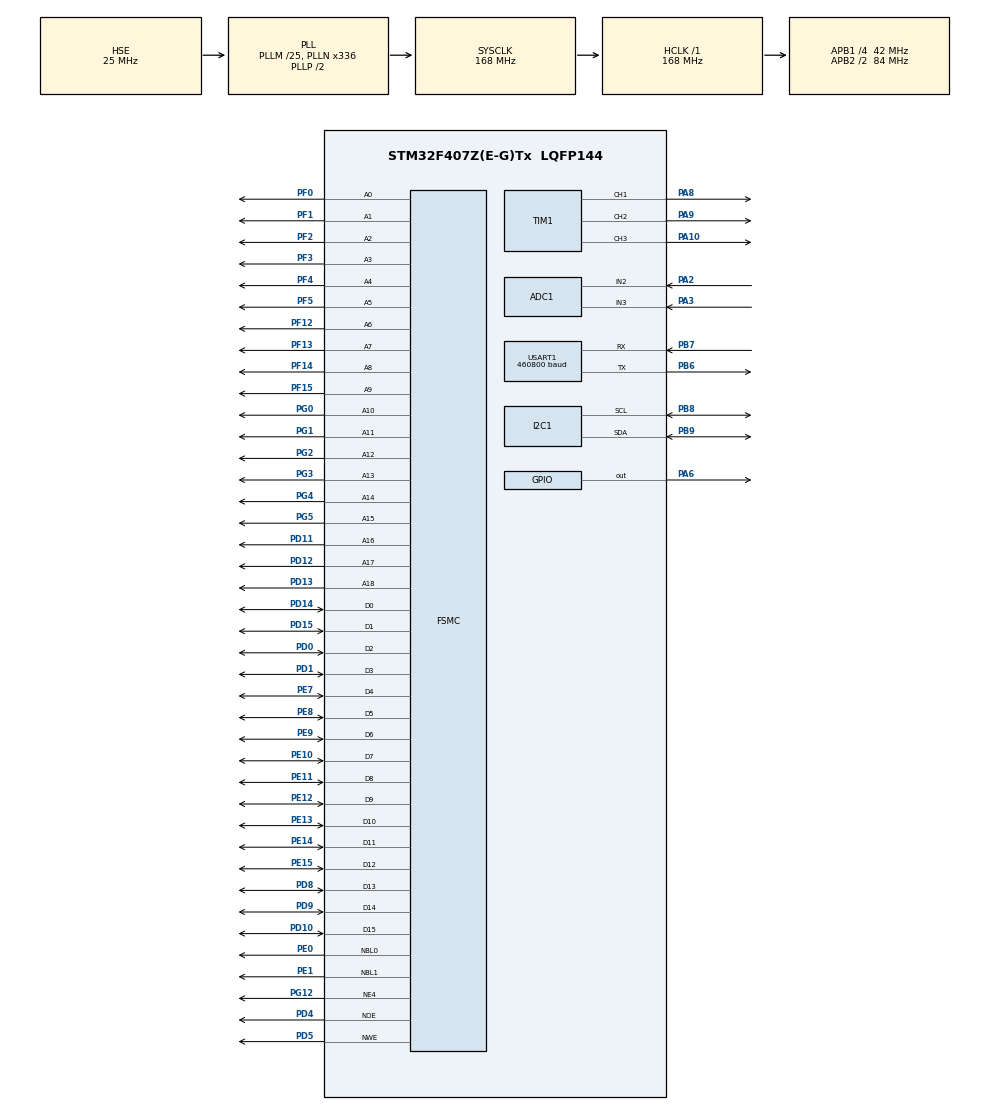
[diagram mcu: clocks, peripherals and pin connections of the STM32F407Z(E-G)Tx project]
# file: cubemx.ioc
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ADC1.Channel-6\#ChannelRegularConversion=ADC_CHANNEL_3
ADC1.Channel-7\#ChannelInjectedConversion=ADC_CHANNEL_2
ADC1.Channel-9\#ChannelInjectedConversion=ADC_CHANNEL_3
ADC1.ExternalTrigInjecConv=ADC_EXTERNALTRIGINJECCONV_T1_TRGO
ADC1.InjNumberOfConversion=2
ADC1.InjectedOffset-7\#ChannelInjectedConversion=0
ADC1.InjectedOffset-9\#ChannelInjectedConversion=0
ADC1.InjectedRank-7\#ChannelInjectedConversion=1
ADC1.InjectedRank-9\#ChannelInjectedConversion=2
ADC1.NbrOfConversion=1
ADC1.NbrOfConversionFlag=1
ADC1.Rank-6\#ChannelRegularConversion=1
ADC1.SamplingTime-6\#ChannelRegularConversion=ADC_SAMPLETIME_3CYCLES
ADC1.SamplingTime-7\#ChannelInjectedConversion=ADC_SAMPLETIME_15CYCLES
ADC1.SamplingTime-9\#ChannelInjectedConversion=ADC_SAMPLETIME_15CYCLES
ADC1.master=1
FSMC.WriteOperation1=FSMC_WRITE_OPERATION_ENABLE
I2C1.I2C_Mode=I2C_Fast
Mcu.Family=STM32F4
Mcu.Name=STM32F407Z(E-G)Tx
Mcu.Package=LQFP144
NVIC.ADC_IRQn=true\:0\:0\:false\:false\:true\:true\:true\:true
NVIC.PriorityGroup=NVIC_PRIORITYGROUP_4
NVIC.TIM1_UP_TIM10_IRQn=true\:0\:0\:false\:false\:true\:true\:true\:true
NVIC.TIM2_IRQn=true\:0\:0\:false\:false\:true\:true\:true\:true
PA10.Signal=S_TIM1_CH3
PA2.Signal=ADCx_IN2
PA3.Signal=ADCx_IN3
PA6.GPIO_Speed=GPIO_SPEED_FREQ_MEDIUM
PA6.Signal=GPIO_Output
PA8.Signal=S_TIM1_CH1
PA9.Signal=S_TIM1_CH2
PB6.Mode=Asynchronous
PB6.Signal=USART1_TX
PB7.Mode=Asynchronous
PB7.Signal=USART1_RX
PB8.Mode=I2C
PB8.Signal=I2C1_SCL
PB9.Mode=I2C
PB9.Signal=I2C1_SDA
PD0.Signal=FSMC_D2_DA2
PD1.Signal=FSMC_D3_DA3
PD10.Signal=FSMC_D15_DA15
PD11.Signal=FSMC_A16_CLE
PD12.Signal=FSMC_A17_ALE
PD13.Signal=FSMC_A18
PD14.Signal=FSMC_D0_DA0
PD15.Signal=FSMC_D1_DA1
PD4.Signal=FSMC_NOE
PD5.Signal=FSMC_NWE
PD8.Signal=FSMC_D13_DA13
PD9.Signal=FSMC_D14_DA14
PE0.Signal=FSMC_NBL0
PE1.Signal=FSMC_NBL1
PE10.Signal=FSMC_D7_DA7
PE11.Signal=FSMC_D8_DA8
PE12.Signal=FSMC_D9_DA9
PE13.Signal=FSMC_D10_DA10
PE14.Signal=FSMC_D11_DA11
PE15.Signal=FSMC_D12_DA12
PE7.Signal=FSMC_D4_DA4
PE8.Signal=FSMC_D5_DA5
PE9.Signal=FSMC_D6_DA6
PF0.Signal=FSMC_A0
PF1.Signal=FSMC_A1
PF12.Signal=FSMC_A6
PF13.Signal=FSMC_A7
PF14.Signal=FSMC_A8
PF15.Signal=FSMC_A9
PF2.Signal=FSMC_A2
PF3.Signal=FSMC_A3
PF4.Signal=FSMC_A4
PF5.Signal=FSMC_A5
PG0.Signal=FSMC_A10
PG1.Signal=FSMC_A11
PG12.Mode=NorPsramChipSelect4_1
PG12.Signal=FSMC_NE4
PG2.Signal=FSMC_A12
PG3.Signal=FSMC_A13
PG4.Signal=FSMC_A14
PG5.Signal=FSMC_A15
PH0-OSC_IN.Mode=HSE-External-Oscillator
PH0-OSC_IN.Signal=RCC_OSC_IN
PH1-OSC_OUT.Mode=HSE-External-Oscillator
PH1-OSC_OUT.Signal=RCC_OSC_OUT
ProjectManager.HeapSize=0x200
ProjectManager.StackSize=0x400
ProjectManager.TargetToolchain=EWARM V8.50
RCC.48MHZClocksFreq_Value=84000000
RCC.AHBFreq_Value=168000000
RCC.APB1CLKDivider=RCC_HCLK_DIV4
RCC.APB1Freq_Value=42000000
RCC.APB1TimFreq_Value=84000000
RCC.APB2CLKDivider=RCC_HCLK_DIV2
RCC.APB2Freq_Value=84000000
RCC.APB2TimFreq_Value=168000000
RCC.CortexFreq_Value=168000000
RCC.HCLKFreq_Value=168000000
RCC.HSE_VALUE=25000000
RCC.HSI_VALUE=16000000
RCC.LSE_VALUE=32768
RCC.PLLM=25
RCC.PLLN=336
RCC.PLLSourceVirtual=RCC_PLLSOURCE_HSE
RCC.SYSCLKFreq_VALUE=168000000
RCC.SYSCLKSource=RCC_SYSCLKSOURCE_PLLCLK
RCC.VCOOutputFreq_Value=336000000
SH.ADCx_IN2.0=ADC1_IN2,IN2
SH.ADCx_IN3.0=ADC1_IN3,IN3
SH.FSMC_A0.0=FSMC_A0,19b-a1
SH.FSMC_A1.0=FSMC_A1,19b-a1
SH.FSMC_A10.0=FSMC_A10,19b-a1
SH.FSMC_A11.0=FSMC_A11,19b-a1
SH.FSMC_A12.0=FSMC_A12,19b-a1
SH.FSMC_A13.0=FSMC_A13,19b-a1
SH.FSMC_A14.0=FSMC_A14,19b-a1
SH.FSMC_A15.0=FSMC_A15,19b-a1
SH.FSMC_A16_CLE.0=FSMC_A16,19b-a1
SH.FSMC_A17_ALE.0=FSMC_A17,19b-a1
SH.FSMC_A18.0=FSMC_A18,19b-a1
SH.FSMC_A2.0=FSMC_A2,19b-a1
SH.FSMC_A3.0=FSMC_A3,19b-a1
SH.FSMC_A4.0=FSMC_A4,19b-a1
SH.FSMC_A5.0=FSMC_A5,19b-a1
SH.FSMC_A6.0=FSMC_A6,19b-a1
SH.FSMC_A7.0=FSMC_A7,19b-a1
SH.FSMC_A8.0=FSMC_A8,19b-a1
SH.FSMC_A9.0=FSMC_A9,19b-a1
SH.FSMC_D0_DA0.0=FSMC_D0,16b-d1
SH.FSMC_D10_DA10.0=FSMC_D10,16b-d1
SH.FSMC_D11_DA11.0=FSMC_D11,16b-d1
SH.FSMC_D12_DA12.0=FSMC_D12,16b-d1
SH.FSMC_D13_DA13.0=FSMC_D13,16b-d1
SH.FSMC_D14_DA14.0=FSMC_D14,16b-d1
SH.FSMC_D15_DA15.0=FSMC_D15,16b-d1
SH.FSMC_D1_DA1.0=FSMC_D1,16b-d1
SH.FSMC_D2_DA2.0=FSMC_D2,16b-d1
SH.FSMC_D3_DA3.0=FSMC_D3,16b-d1
SH.FSMC_D4_DA4.0=FSMC_D4,16b-d1
SH.FSMC_D5_DA5.0=FSMC_D5,16b-d1
SH.FSMC_D6_DA6.0=FSMC_D6,16b-d1
SH.FSMC_D7_DA7.0=FSMC_D7,16b-d1
SH.FSMC_D8_DA8.0=FSMC_D8,16b-d1
SH.FSMC_D9_DA9.0=FSMC_D9,16b-d1
SH.FSMC_NBL0.0=FSMC_NBL0,2ByteEnable1
SH.FSMC_NBL1.0=FSMC_NBL1,2ByteEnable1
SH.FSMC_NOE.0=FSMC_NOE,Sram1
SH.FSMC_NWE.0=FSMC_NWE,Sram1
SH.S_TIM1_CH1.0=TIM1_CH1,PWM Generation1 CH1
SH.S_TIM1_CH2.0=TIM1_CH2,PWM Generation2 CH2
SH.S_TIM1_CH3.0=TIM1_CH3,PWM Generation3 CH3
TIM1.AutoReloadPreload=TIM_AUTORELOAD_PRELOAD_ENABLE
TIM1.Channel-PWM\ Generation1\ CH1=TIM_CHANNEL_1
TIM1.Channel-PWM\ Generation2\ CH2=TIM_CHANNEL_2
TIM1.Channel-PWM\ Generation3\ CH3=TIM_CHANNEL_3
TIM1.CounterMode=TIM_COUNTERMODE_CENTERALIGNED1
TIM1.Period=(168000/15/2)-1
TIM1.Pulse-PWM\ Generation1\ CH1=0
TIM1.Pulse-PWM\ Generation2\ CH2=0
TIM1.Pulse-PWM\ Generation3\ CH3=0
TIM1.RepetitionCounter=1
TIM1.TIM_MasterOutputTrigger=TIM_TRGO_UPDATE
TIM1.TIM_MasterSlaveMode=TIM_MASTERSLAVEMODE_ENABLE
TIM2.AutoReloadPreload=TIM_AUTORELOAD_PRELOAD_ENABLE
TIM2.Period=499
TIM2.Prescaler=168-1
USART1.BaudRate=460800
USART1.VirtualMode=VM_ASYNC
VP_TIM1_VS_ClockSourceINT.Mode=Internal
VP_TIM2_VS_ClockSourceINT.Mode=Internal
board=custom

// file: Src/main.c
/* USER CODE BEGIN Header */
/**
  ******************************************************************************
  * @file           : main.c
  * @brief          : Main program body
  ******************************************************************************
  * @attention
  *
  * Copyright (c) 2026 STMicroelectronics.
  * All rights reserved.
  *
  * This software is licensed under terms that can be found in the LICENSE file
  * in the root directory of this software component.
  * If no LICENSE file comes with this software, it is provided AS-IS.
  *
  ******************************************************************************
  */
/* USER CODE END Header */
#include "main.h"

/* USER CODE BEGIN Includes */
#include "drv_common.h"
/* USER CODE END Includes */

ADC_HandleTypeDef hadc1;

I2C_HandleTypeDef hi2c1;

TIM_HandleTypeDef htim1;
TIM_HandleTypeDef htim2;

UART_HandleTypeDef huart1;

SRAM_HandleTypeDef hsram1;

void SystemClock_Config(void);
static void MX_GPIO_Init(void);
static void MX_FSMC_Init(void);
static void MX_I2C1_Init(void);
static void MX_TIM1_Init(void);
static void MX_USART1_UART_Init(void);
static void MX_TIM2_Init(void);
static void MX_ADC1_Init(void);

/* USER CODE BEGIN 0 */
void MX_init(void)
{
  MX_GPIO_Init();
  MX_FSMC_Init();
  MX_I2C1_Init();
  MX_TIM1_Init();
  MX_TIM2_Init();
  MX_ADC1_Init();
}

/* USER CODE END 0 */

__WEAK int main(void)
{

  /* MCU Configuration--------------------------------------------------------*/

  /* Reset of all peripherals, Initializes the Flash interface and the Systick. */
  HAL_Init();

  /* Configure the system clock */
  SystemClock_Config();

  /* Initialize all configured peripherals */
  MX_GPIO_Init();
  MX_FSMC_Init();
  MX_I2C1_Init();
  MX_TIM1_Init();
  MX_USART1_UART_Init();
  MX_TIM2_Init();
  MX_ADC1_Init();

  /* Infinite loop */
  while (1)
  {

  }
}

void SystemClock_Config(void)
{
  RCC_OscInitTypeDef RCC_OscInitStruct = {0};
  RCC_ClkInitTypeDef RCC_ClkInitStruct = {0};

  /** Configure the main internal regulator output voltage
  */
  __HAL_RCC_PWR_CLK_ENABLE();
  __HAL_PWR_VOLTAGESCALING_CONFIG(PWR_REGULATOR_VOLTAGE_SCALE1);

  /** Initializes the RCC Oscillators according to the specified parameters
  * in the RCC_OscInitTypeDef structure.
  */
  RCC_OscInitStruct.OscillatorType = RCC_OSCILLATORTYPE_HSE;
  RCC_OscInitStruct.HSEState = RCC_HSE_ON;
  RCC_OscInitStruct.PLL.PLLState = RCC_PLL_ON;
  RCC_OscInitStruct.PLL.PLLSource = RCC_PLLSOURCE_HSE;
  RCC_OscInitStruct.PLL.PLLM = 25;
  RCC_OscInitStruct.PLL.PLLN = 336;
  RCC_OscInitStruct.PLL.PLLP = RCC_PLLP_DIV2;
  RCC_OscInitStruct.PLL.PLLQ = 4;
  if (HAL_RCC_OscConfig(&RCC_OscInitStruct) != HAL_OK)
  {
    Error_Handler();
  }

  /** Initializes the CPU, AHB and APB buses clocks
  */
  RCC_ClkInitStruct.ClockType = RCC_CLOCKTYPE_HCLK|RCC_CLOCKTYPE_SYSCLK
                              |RCC_CLOCKTYPE_PCLK1|RCC_CLOCKTYPE_PCLK2;
  RCC_ClkInitStruct.SYSCLKSource = RCC_SYSCLKSOURCE_PLLCLK;
  RCC_ClkInitStruct.AHBCLKDivider = RCC_SYSCLK_DIV1;
  RCC_ClkInitStruct.APB1CLKDivider = RCC_HCLK_DIV4;
  RCC_ClkInitStruct.APB2CLKDivider = RCC_HCLK_DIV2;

  if (HAL_RCC_ClockConfig(&RCC_ClkInitStruct, FLASH_LATENCY_5) != HAL_OK)
  {
    Error_Handler();
  }
}

static void MX_ADC1_Init(void)
{

  ADC_ChannelConfTypeDef sConfig = {0};
  ADC_InjectionConfTypeDef sConfigInjected = {0};

  /** Configure the global features of the ADC (Clock, Resolution, Data Alignment and number of conversion)
  */
  hadc1.Instance = ADC1;
  hadc1.Init.ClockPrescaler = ADC_CLOCK_SYNC_PCLK_DIV4;
  hadc1.Init.Resolution = ADC_RESOLUTION_12B;
  hadc1.Init.ScanConvMode = ENABLE;
  hadc1.Init.ContinuousConvMode = DISABLE;
  hadc1.Init.DiscontinuousConvMode = DISABLE;
  hadc1.Init.ExternalTrigConvEdge = ADC_EXTERNALTRIGCONVEDGE_NONE;
  hadc1.Init.ExternalTrigConv = ADC_SOFTWARE_START;
  hadc1.Init.DataAlign = ADC_DATAALIGN_RIGHT;
  hadc1.Init.NbrOfConversion = 1;
  hadc1.Init.DMAContinuousRequests = DISABLE;
  hadc1.Init.EOCSelection = ADC_EOC_SINGLE_CONV;
  if (HAL_ADC_Init(&hadc1) != HAL_OK)
  {
    Error_Handler();
  }

  /** Configure for the selected ADC regular channel its corresponding rank in the sequencer and its sample time.
  */
  sConfig.Channel = ADC_CHANNEL_3;
  sConfig.Rank = 1;
  sConfig.SamplingTime = ADC_SAMPLETIME_3CYCLES;
  if (HAL_ADC_ConfigChannel(&hadc1, &sConfig) != HAL_OK)
  {
    Error_Handler();
  }

  /** Configures for the selected ADC injected channel its corresponding rank in the sequencer and its sample time
  */
  /* PA2=IN2 → Ia, PA3=IN3 → Ib；TIM1 TRGO(Update) 在中心对齐 PWM 谷底触发 */
  sConfigInjected.InjectedChannel = ADC_CHANNEL_2;
  sConfigInjected.InjectedRank = 1;
  sConfigInjected.InjectedNbrOfConversion = 2;
  sConfigInjected.InjectedSamplingTime = ADC_SAMPLETIME_28CYCLES;
  sConfigInjected.ExternalTrigInjecConvEdge = ADC_EXTERNALTRIGINJECCONVEDGE_RISING;
  sConfigInjected.ExternalTrigInjecConv = ADC_EXTERNALTRIGINJECCONV_T1_TRGO;
  sConfigInjected.AutoInjectedConv = DISABLE;
  sConfigInjected.InjectedDiscontinuousConvMode = DISABLE;
  sConfigInjected.InjectedOffset = 0;
  if (HAL_ADCEx_InjectedConfigChannel(&hadc1, &sConfigInjected) != HAL_OK)
  {
    Error_Handler();
  }

  /** Configures for the selected ADC injected channel its corresponding rank in the sequencer and its sample time
  */
  sConfigInjected.InjectedChannel = ADC_CHANNEL_3;
  sConfigInjected.InjectedRank = 2;
  if (HAL_ADCEx_InjectedConfigChannel(&hadc1, &sConfigInjected) != HAL_OK)
  {
    Error_Handler();
  }

}

static void MX_I2C1_Init(void)
{

  hi2c1.Instance = I2C1;
  hi2c1.Init.ClockSpeed = 400000;
  hi2c1.Init.DutyCycle = I2C_DUTYCYCLE_2;
  hi2c1.Init.OwnAddress1 = 0;
  hi2c1.Init.AddressingMode = I2C_ADDRESSINGMODE_7BIT;
  hi2c1.Init.DualAddressMode = I2C_DUALADDRESS_DISABLE;
  hi2c1.Init.OwnAddress2 = 0;
  hi2c1.Init.GeneralCallMode = I2C_GENERALCALL_DISABLE;
  hi2c1.Init.NoStretchMode = I2C_NOSTRETCH_DISABLE;
  if (HAL_I2C_Init(&hi2c1) != HAL_OK)
  {
    Error_Handler();
  }

}

static void MX_TIM1_Init(void)
{

  TIM_ClockConfigTypeDef sClockSourceConfig = {0};
  TIM_MasterConfigTypeDef sMasterConfig = {0};
  TIM_OC_InitTypeDef sConfigOC = {0};
  TIM_BreakDeadTimeConfigTypeDef sBreakDeadTimeConfig = {0};

  htim1.Instance = TIM1;
  htim1.Init.Prescaler = 0;
  htim1.Init.CounterMode = TIM_COUNTERMODE_CENTERALIGNED1;
  htim1.Init.Period = (168000/20/2)-1;
  htim1.Init.ClockDivision = TIM_CLOCKDIVISION_DIV1;
  htim1.Init.RepetitionCounter = 7;
  htim1.Init.AutoReloadPreload = TIM_AUTORELOAD_PRELOAD_ENABLE;
  if (HAL_TIM_Base_Init(&htim1) != HAL_OK)
  {
    Error_Handler();
  }
  sClockSourceConfig.ClockSource = TIM_CLOCKSOURCE_INTERNAL;
  if (HAL_TIM_ConfigClockSource(&htim1, &sClockSourceConfig) != HAL_OK)
  {
    Error_Handler();
  }
  if (HAL_TIM_PWM_Init(&htim1) != HAL_OK)
  {
    Error_Handler();
  }
  /* TRGO=Update 供 ADC 注入触发；仅作主触发时 MSM 应关闭，避免 TRGO 多延迟一拍 */
  sMasterConfig.MasterOutputTrigger = TIM_TRGO_UPDATE;
  sMasterConfig.MasterSlaveMode = TIM_MASTERSLAVEMODE_DISABLE;
  if (HAL_TIMEx_MasterConfigSynchronization(&htim1, &sMasterConfig) != HAL_OK)
  {
    Error_Handler();
  }
  sConfigOC.OCMode = TIM_OCMODE_PWM1;
  sConfigOC.Pulse = 0;
  sConfigOC.OCPolarity = TIM_OCPOLARITY_HIGH;
  sConfigOC.OCNPolarity = TIM_OCNPOLARITY_HIGH;
  sConfigOC.OCFastMode = TIM_OCFAST_DISABLE;
  sConfigOC.OCIdleState = TIM_OCIDLESTATE_RESET;
  sConfigOC.OCNIdleState = TIM_OCNIDLESTATE_RESET;
  if (HAL_TIM_PWM_ConfigChannel(&htim1, &sConfigOC, TIM_CHANNEL_1) != HAL_OK)
  {
    Error_Handler();
  }
  if (HAL_TIM_PWM_ConfigChannel(&htim1, &sConfigOC, TIM_CHANNEL_2) != HAL_OK)
  {
    Error_Handler();
  }
  if (HAL_TIM_PWM_ConfigChannel(&htim1, &sConfigOC, TIM_CHANNEL_3) != HAL_OK)
  {
    Error_Handler();
  }
  sBreakDeadTimeConfig.OffStateRunMode = TIM_OSSR_DISABLE;
  sBreakDeadTimeConfig.OffStateIDLEMode = TIM_OSSI_DISABLE;
  sBreakDeadTimeConfig.LockLevel = TIM_LOCKLEVEL_OFF;
  sBreakDeadTimeConfig.DeadTime = 0;
  sBreakDeadTimeConfig.BreakState = TIM_BREAK_DISABLE;
  sBreakDeadTimeConfig.BreakPolarity = TIM_BREAKPOLARITY_HIGH;
  sBreakDeadTimeConfig.AutomaticOutput = TIM_AUTOMATICOUTPUT_DISABLE;
  if (HAL_TIMEx_ConfigBreakDeadTime(&htim1, &sBreakDeadTimeConfig) != HAL_OK)
  {
    Error_Handler();
  }
  HAL_TIM_MspPostInit(&htim1);

}

static void MX_TIM2_Init(void)
{

  TIM_ClockConfigTypeDef sClockSourceConfig = {0};
  TIM_MasterConfigTypeDef sMasterConfig = {0};

  htim2.Instance = TIM2;
  htim2.Init.Prescaler = 168-1;
  htim2.Init.CounterMode = TIM_COUNTERMODE_UP;
  htim2.Init.Period = 499;
  htim2.Init.ClockDivision = TIM_CLOCKDIVISION_DIV1;
  htim2.Init.AutoReloadPreload = TIM_AUTORELOAD_PRELOAD_ENABLE;
  if (HAL_TIM_Base_Init(&htim2) != HAL_OK)
  {
    Error_Handler();
  }
  sClockSourceConfig.ClockSource = TIM_CLOCKSOURCE_INTERNAL;
  if (HAL_TIM_ConfigClockSource(&htim2, &sClockSourceConfig) != HAL_OK)
  {
    Error_Handler();
  }
  sMasterConfig.MasterOutputTrigger = TIM_TRGO_RESET;
  sMasterConfig.MasterSlaveMode = TIM_MASTERSLAVEMODE_DISABLE;
  if (HAL_TIMEx_MasterConfigSynchronization(&htim2, &sMasterConfig) != HAL_OK)
  {
    Error_Handler();
  }

}

static void MX_USART1_UART_Init(void)
{

  huart1.Instance = USART1;
  huart1.Init.BaudRate = 460800;
  huart1.Init.WordLength = UART_WORDLENGTH_8B;
  huart1.Init.StopBits = UART_STOPBITS_1;
  huart1.Init.Parity = UART_PARITY_NONE;
  huart1.Init.Mode = UART_MODE_TX_RX;
  huart1.Init.HwFlowCtl = UART_HWCONTROL_NONE;
  huart1.Init.OverSampling = UART_OVERSAMPLING_16;
  if (HAL_UART_Init(&huart1) != HAL_OK)
  {
    Error_Handler();
  }

}

static void MX_GPIO_Init(void)
{
  GPIO_InitTypeDef GPIO_InitStruct = {0};

  /* GPIO Ports Clock Enable */
  __HAL_RCC_GPIOF_CLK_ENABLE();
  __HAL_RCC_GPIOH_CLK_ENABLE();
  __HAL_RCC_GPIOA_CLK_ENABLE();
  __HAL_RCC_GPIOG_CLK_ENABLE();
  __HAL_RCC_GPIOE_CLK_ENABLE();
  __HAL_RCC_GPIOD_CLK_ENABLE();
  __HAL_RCC_GPIOB_CLK_ENABLE();

  /*Configure GPIO pin Output Level */
  HAL_GPIO_WritePin(GPIOA, GPIO_PIN_6, GPIO_PIN_RESET);

  /*Configure GPIO pin : PA6 */
  GPIO_InitStruct.Pin = GPIO_PIN_6;
  GPIO_InitStruct.Mode = GPIO_MODE_OUTPUT_PP;
  GPIO_InitStruct.Pull = GPIO_NOPULL;
  GPIO_InitStruct.Speed = GPIO_SPEED_FREQ_MEDIUM;
  HAL_GPIO_Init(GPIOA, &GPIO_InitStruct);

}

/* FSMC initialization function */
static void MX_FSMC_Init(void)
{

  FSMC_NORSRAM_TimingTypeDef Timing = {0};

  /** Perform the SRAM1 memory initialization sequence
  */
  hsram1.Instance = FSMC_NORSRAM_DEVICE;
  hsram1.Extended = FSMC_NORSRAM_EXTENDED_DEVICE;
  /* hsram1.Init */
  hsram1.Init.NSBank = FSMC_NORSRAM_BANK4;
  hsram1.Init.DataAddressMux = FSMC_DATA_ADDRESS_MUX_DISABLE;
  hsram1.Init.MemoryType = FSMC_MEMORY_TYPE_SRAM;
  hsram1.Init.MemoryDataWidth = FSMC_NORSRAM_MEM_BUS_WIDTH_16;
  hsram1.Init.BurstAccessMode = FSMC_BURST_ACCESS_MODE_DISABLE;
  hsram1.Init.WaitSignalPolarity = FSMC_WAIT_SIGNAL_POLARITY_LOW;
  hsram1.Init.WrapMode = FSMC_WRAP_MODE_DISABLE;
  hsram1.Init.WaitSignalActive = FSMC_WAIT_TIMING_BEFORE_WS;
  hsram1.Init.WriteOperation = FSMC_WRITE_OPERATION_ENABLE;
  hsram1.Init.WaitSignal = FSMC_WAIT_SIGNAL_DISABLE;
  hsram1.Init.ExtendedMode = FSMC_EXTENDED_MODE_DISABLE;
  hsram1.Init.AsynchronousWait = FSMC_ASYNCHRONOUS_WAIT_DISABLE;
  hsram1.Init.WriteBurst = FSMC_WRITE_BURST_DISABLE;
  hsram1.Init.PageSize = FSMC_PAGE_SIZE_NONE;
  /* Timing */
  Timing.AddressSetupTime = 15;
  Timing.AddressHoldTime = 15;
  Timing.DataSetupTime = 255;
  Timing.BusTurnAroundDuration = 15;
  Timing.CLKDivision = 16;
  Timing.DataLatency = 17;
  Timing.AccessMode = FSMC_ACCESS_MODE_A;
  /* ExtTiming */

  if (HAL_SRAM_Init(&hsram1, &Timing, NULL) != HAL_OK)
  {
    Error_Handler( );
  }

}

/* drv_common.h 将 Error_Handler() 宏映射到 _Error_Handler；此处取消宏以便定义弱兼容符号 */
#undef Error_Handler
void Error_Handler(void)
{
  /* USER CODE BEGIN Error_Handler_Debug */
  _Error_Handler("Error_Handler", 0);
  /* USER CODE END Error_Handler_Debug */
}
